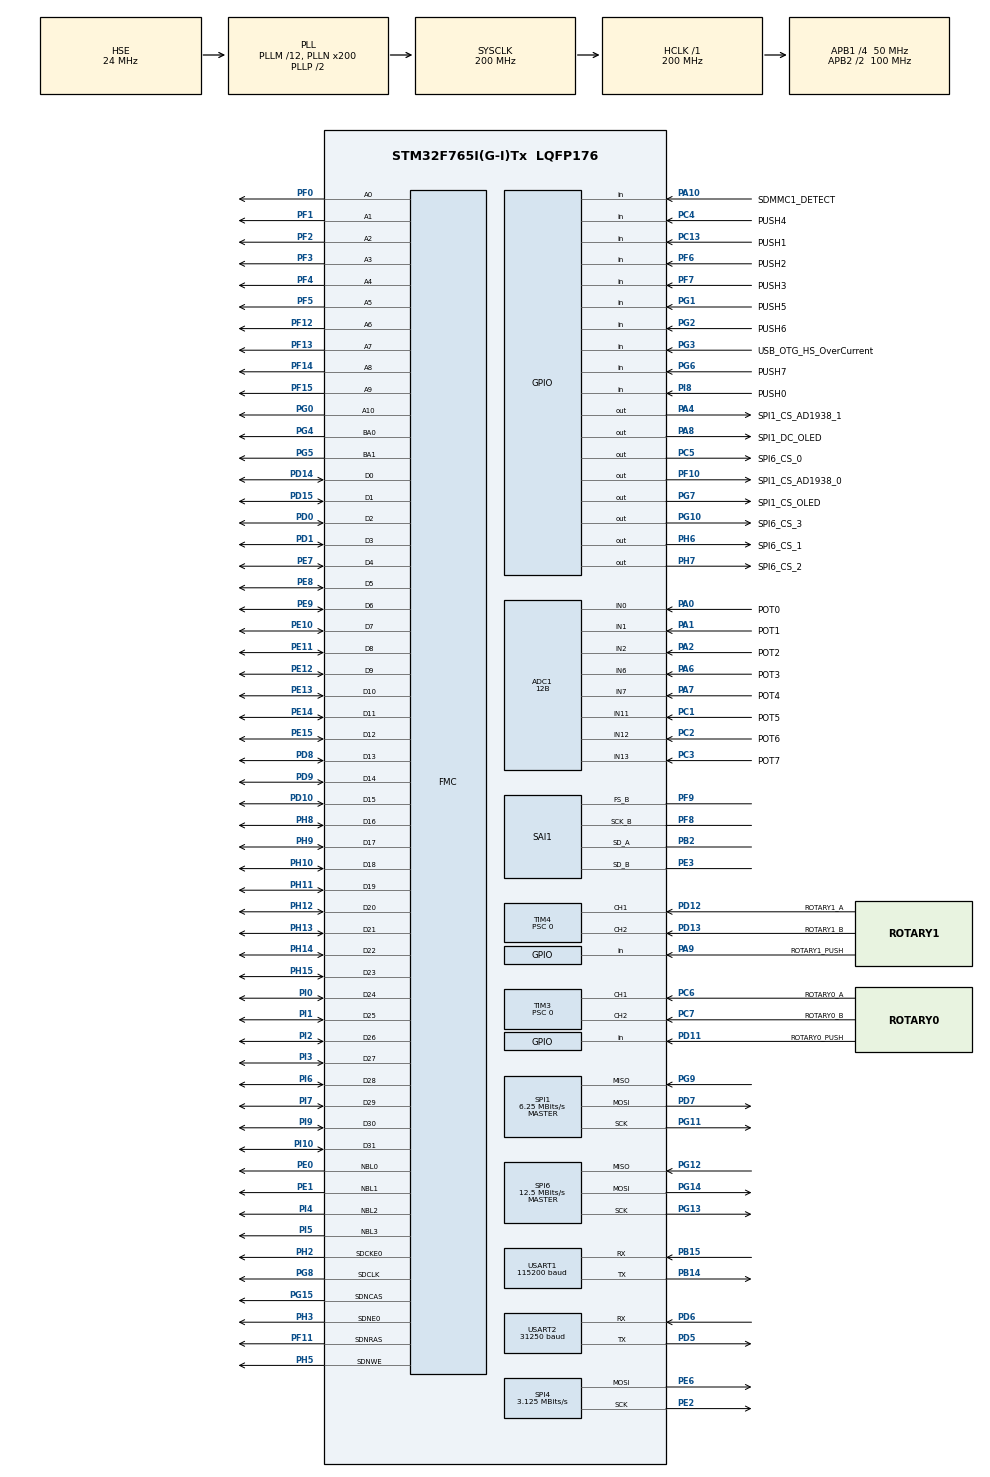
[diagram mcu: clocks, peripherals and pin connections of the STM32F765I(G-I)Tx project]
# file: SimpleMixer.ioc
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ADC1.Channel-0\#ChannelRegularConversion=ADC_CHANNEL_0
ADC1.Channel-1\#ChannelRegularConversion=ADC_CHANNEL_1
ADC1.Channel-2\#ChannelRegularConversion=ADC_CHANNEL_2
ADC1.Channel-3\#ChannelRegularConversion=ADC_CHANNEL_6
ADC1.Channel-4\#ChannelRegularConversion=ADC_CHANNEL_7
ADC1.Channel-5\#ChannelRegularConversion=ADC_CHANNEL_11
ADC1.Channel-6\#ChannelRegularConversion=ADC_CHANNEL_12
ADC1.Channel-7\#ChannelRegularConversion=ADC_CHANNEL_13
ADC1.ClockPrescaler=ADC_CLOCK_SYNC_PCLK_DIV8
ADC1.ContinuousConvMode=ENABLE
ADC1.DMAContinuousRequests=ENABLE
ADC1.DataAlign=ADC_DATAALIGN_RIGHT
ADC1.DiscontinuousConvMode=DISABLE
ADC1.EOCSelection=ADC_EOC_SEQ_CONV
ADC1.EnableAnalogWatchDog=false
ADC1.ExternalTrigConv=ADC_SOFTWARE_START
ADC1.ExternalTrigConvEdge=ADC_EXTERNALTRIGCONVEDGE_NONE
ADC1.InjNumberOfConversion=0
ADC1.NbrOfConversion=8
ADC1.NbrOfConversionFlag=1
ADC1.Rank-0\#ChannelRegularConversion=1
ADC1.Rank-1\#ChannelRegularConversion=2
ADC1.Rank-2\#ChannelRegularConversion=3
ADC1.Rank-3\#ChannelRegularConversion=4
ADC1.Rank-4\#ChannelRegularConversion=5
ADC1.Rank-5\#ChannelRegularConversion=6
ADC1.Rank-6\#ChannelRegularConversion=7
ADC1.Rank-7\#ChannelRegularConversion=8
ADC1.Resolution=ADC_RESOLUTION_12B
ADC1.SamplingTime-0\#ChannelRegularConversion=ADC_SAMPLETIME_480CYCLES
ADC1.SamplingTime-1\#ChannelRegularConversion=ADC_SAMPLETIME_480CYCLES
ADC1.SamplingTime-2\#ChannelRegularConversion=ADC_SAMPLETIME_480CYCLES
ADC1.SamplingTime-3\#ChannelRegularConversion=ADC_SAMPLETIME_480CYCLES
ADC1.SamplingTime-4\#ChannelRegularConversion=ADC_SAMPLETIME_480CYCLES
ADC1.SamplingTime-5\#ChannelRegularConversion=ADC_SAMPLETIME_480CYCLES
ADC1.SamplingTime-6\#ChannelRegularConversion=ADC_SAMPLETIME_480CYCLES
ADC1.SamplingTime-7\#ChannelRegularConversion=ADC_SAMPLETIME_480CYCLES
ADC1.ScanConvMode=ENABLE
ADC1.master=1
CORTEX_M7.FlashInterface=TCM_Enabled
Dma.ADC1.0.Direction=DMA_PERIPH_TO_MEMORY
Dma.ADC1.0.FIFOMode=DMA_FIFOMODE_DISABLE
Dma.ADC1.0.Instance=DMA2_Stream4
Dma.ADC1.0.MemDataAlignment=DMA_MDATAALIGN_HALFWORD
Dma.ADC1.0.MemInc=DMA_MINC_ENABLE
Dma.ADC1.0.Mode=DMA_CIRCULAR
Dma.ADC1.0.PeriphDataAlignment=DMA_PDATAALIGN_HALFWORD
Dma.ADC1.0.PeriphInc=DMA_PINC_DISABLE
Dma.ADC1.0.Priority=DMA_PRIORITY_LOW
Dma.Request0=ADC1
Dma.Request1=SAI1_A
Dma.Request2=SAI1_B
Dma.Request3=SPI4_TX
Dma.SAI1_A.1.Direction=DMA_PERIPH_TO_MEMORY
Dma.SAI1_A.1.FIFOMode=DMA_FIFOMODE_ENABLE
Dma.SAI1_A.1.FIFOThreshold=DMA_FIFO_THRESHOLD_HALFFULL
Dma.SAI1_A.1.Instance=DMA2_Stream1
Dma.SAI1_A.1.MemBurst=DMA_MBURST_SINGLE
Dma.SAI1_A.1.MemDataAlignment=DMA_MDATAALIGN_WORD
Dma.SAI1_A.1.MemInc=DMA_MINC_ENABLE
Dma.SAI1_A.1.Mode=DMA_CIRCULAR
Dma.SAI1_A.1.PeriphBurst=DMA_PBURST_SINGLE
Dma.SAI1_A.1.PeriphDataAlignment=DMA_PDATAALIGN_WORD
Dma.SAI1_A.1.PeriphInc=DMA_PINC_DISABLE
Dma.SAI1_A.1.Priority=DMA_PRIORITY_HIGH
Dma.SAI1_B.2.Direction=DMA_MEMORY_TO_PERIPH
Dma.SAI1_B.2.FIFOMode=DMA_FIFOMODE_ENABLE
Dma.SAI1_B.2.FIFOThreshold=DMA_FIFO_THRESHOLD_HALFFULL
Dma.SAI1_B.2.Instance=DMA2_Stream0
Dma.SAI1_B.2.MemBurst=DMA_MBURST_SINGLE
Dma.SAI1_B.2.MemDataAlignment=DMA_MDATAALIGN_WORD
Dma.SAI1_B.2.MemInc=DMA_MINC_ENABLE
Dma.SAI1_B.2.Mode=DMA_CIRCULAR
Dma.SAI1_B.2.PeriphBurst=DMA_PBURST_SINGLE
Dma.SAI1_B.2.PeriphDataAlignment=DMA_PDATAALIGN_WORD
Dma.SAI1_B.2.PeriphInc=DMA_PINC_DISABLE
Dma.SAI1_B.2.Priority=DMA_PRIORITY_HIGH
Dma.SPI4_TX.3.Direction=DMA_MEMORY_TO_PERIPH
Dma.SPI4_TX.3.FIFOMode=DMA_FIFOMODE_ENABLE
Dma.SPI4_TX.3.FIFOThreshold=DMA_FIFO_THRESHOLD_FULL
Dma.SPI4_TX.3.Instance=DMA2_Stream2
Dma.SPI4_TX.3.MemBurst=DMA_MBURST_INC8
Dma.SPI4_TX.3.MemDataAlignment=DMA_MDATAALIGN_BYTE
Dma.SPI4_TX.3.MemInc=DMA_MINC_ENABLE
Dma.SPI4_TX.3.Mode=DMA_NORMAL
Dma.SPI4_TX.3.PeriphBurst=DMA_PBURST_SINGLE
Dma.SPI4_TX.3.PeriphDataAlignment=DMA_PDATAALIGN_BYTE
Dma.SPI4_TX.3.PeriphInc=DMA_PINC_DISABLE
Dma.SPI4_TX.3.Priority=DMA_PRIORITY_VERY_HIGH
FMC.CASLatency1=FMC_SDRAM_CAS_LATENCY_2
FMC.ExitSelfRefreshDelay1=7
FMC.LoadToActiveDelay1=2
FMC.RCDDelay1=2
FMC.RPDelay1=2
FMC.RPDelay2=2
FMC.ReadBurst1=FMC_SDRAM_RBURST_ENABLE
FMC.ReadBurst2=FMC_SDRAM_RBURST_ENABLE
FMC.ReadPipeDelay1=FMC_SDRAM_RPIPE_DELAY_0
FMC.RowCycleDelay1=7
FMC.RowCycleDelay2=7
FMC.SDClockPeriod1=FMC_SDRAM_CLOCK_PERIOD_2
FMC.SDClockPeriod2=FMC_SDRAM_CLOCK_PERIOD_2
FMC.SelfRefreshTime1=5
FMC.WriteRecoveryTime1=3
FREERTOS.INCLUDE_uxTaskGetStackHighWaterMark=1
FREERTOS.INCLUDE_vTaskDelayUntil=1
FREERTOS.Tasks01=audio,3,32768,audioTask,Default,NULL,Dynamic,NULL,NULL;GUI,-2,32768,guiTask,Default,NULL,Dynamic,NULL,NULL
FREERTOS.configGENERATE_RUN_TIME_STATS=0
FREERTOS.configTOTAL_HEAP_SIZE=393216
Mcu.Family=STM32F7
Mcu.Name=STM32F765I(G-I)Tx
Mcu.Package=LQFP176
NVIC.DMA2_Stream0_IRQn=true\:5\:0\:false\:false\:true\:true\:false
NVIC.DMA2_Stream1_IRQn=true\:5\:0\:false\:false\:true\:true\:false
NVIC.DMA2_Stream2_IRQn=true\:5\:0\:false\:false\:true\:true\:false
NVIC.DMA2_Stream4_IRQn=true\:5\:0\:false\:false\:true\:true\:false
NVIC.PriorityGroup=NVIC_PRIORITYGROUP_4
NVIC.TIM1_UP_TIM10_IRQn=true\:0\:0\:false\:false\:true\:false\:true
NVIC.TimeBase=TIM1_UP_TIM10_IRQn
NVIC.TimeBaseIP=TIM1
PA0/WKUP.GPIO_Label=POT0
PA0/WKUP.Signal=ADCx_IN0
PA1.GPIO_Label=POT1
PA1.Signal=ADCx_IN1
PA10.GPIO_Label=SDMMC1_DETECT
PA10.GPIO_PuPd=GPIO_PULLUP
PA10.Signal=GPIO_Input
PA13.Mode=Trace_Asynchronous_SW
PA13.Signal=SYS_JTMS-SWDIO
PA14.Mode=Trace_Asynchronous_SW
PA14.Signal=SYS_JTCK-SWCLK
PA2.GPIO_Label=POT2
PA2.Signal=ADCx_IN2
PA3.Signal=USB_OTG_HS_ULPI_D0
PA4.GPIO_Label=SPI1_CS_AD1938_1
PA4.Signal=GPIO_Output
PA5.Signal=USB_OTG_HS_ULPI_CK
PA6.GPIO_Label=POT3
PA6.Signal=ADCx_IN6
PA7.GPIO_Label=POT4
PA7.Signal=ADCx_IN7
PA8.GPIO_Label=SPI1_DC_OLED
PA8.PinState=GPIO_PIN_RESET
PA8.Signal=GPIO_Output
PA9.GPIO_Label=ROTARY1_PUSH
PA9.GPIO_Mode=GPIO_MODE_INPUT
PA9.GPIO_PuPd=GPIO_PULLUP
PA9.Signal=GPIO_Input
PB0.Signal=USB_OTG_HS_ULPI_D1
PB1.Signal=USB_OTG_HS_ULPI_D2
PB10.Signal=USB_OTG_HS_ULPI_D3
PB11.Signal=USB_OTG_HS_ULPI_D4
PB12.Signal=USB_OTG_HS_ULPI_D5
PB13.Signal=USB_OTG_HS_ULPI_D6
PB14.Mode=Asynchronous
PB14.Signal=USART1_TX
PB15.Mode=Asynchronous
PB15.Signal=USART1_RX
PB2.Mode=SAI_A_SyncSlave
PB2.Signal=SAI1_SD_A
PB3.Mode=Trace_Asynchronous_SW
PB3.Signal=SYS_JTDO-SWO
PB5.Signal=USB_OTG_HS_ULPI_D7
PC0.Signal=USB_OTG_HS_ULPI_STP
PC1.GPIO_Label=POT5
PC1.Signal=ADCx_IN11
PC10.Signal=SDMMC1_D2
PC11.Signal=SDMMC1_D3
PC12.Signal=SDMMC1_CK
PC13.GPIO_Label=PUSH1
PC13.GPIO_Mode=GPIO_MODE_INPUT
PC13.GPIO_PuPd=GPIO_PULLUP
PC13.Signal=GPIO_Input
PC14/OSC32_IN.Signal=RCC_OSC32_IN
PC15/OSC32_OUT.Signal=RCC_OSC32_OUT
PC2.GPIO_Label=POT6
PC2.Signal=ADCx_IN12
PC3.GPIO_Label=POT7
PC3.Signal=ADCx_IN13
PC4.GPIO_Label=PUSH4
PC4.GPIO_Mode=GPIO_MODE_INPUT
PC4.GPIO_PuPd=GPIO_PULLUP
PC4.Signal=GPIO_Input
PC5.GPIO_Label=SPI6_CS_0
PC5.PinState=GPIO_PIN_RESET
PC5.Signal=GPIO_Output
PC6.GPIO_Label=ROTARY0_A
PC6.Signal=S_TIM3_CH1
PC7.GPIO_Label=ROTARY0_B
PC7.Signal=S_TIM3_CH2
PC8.Signal=SDMMC1_D0
PC9.Signal=SDMMC1_D1
PD0.Signal=FMC_D2_DA2
PD1.Signal=FMC_D3_DA3
PD10.Signal=FMC_D15_DA15
PD11.GPIO_Label=ROTARY0_PUSH
PD11.GPIO_Mode=GPIO_MODE_INPUT
PD11.GPIO_PuPd=GPIO_PULLUP
PD11.Signal=GPIO_Input
PD12.GPIO_Label=ROTARY1_A
PD12.Signal=S_TIM4_CH1
PD13.GPIO_Label=ROTARY1_B
PD13.Signal=S_TIM4_CH2
PD14.Signal=FMC_D0_DA0
PD15.Signal=FMC_D1_DA1
PD2.Signal=SDMMC1_CMD
PD5.Mode=Asynchronous
PD5.Signal=USART2_TX
PD6.Mode=Asynchronous
PD6.Signal=USART2_RX
PD7.Mode=Full_Duplex_Master
PD7.Signal=SPI1_MOSI
PD8.Signal=FMC_D13_DA13
PD9.Signal=FMC_D14_DA14
PE0.Signal=FMC_NBL0
PE1.Signal=FMC_NBL1
PE10.Signal=FMC_D7_DA7
PE11.Signal=FMC_D8_DA8
PE12.Signal=FMC_D9_DA9
PE13.Signal=FMC_D10_DA10
PE14.Signal=FMC_D11_DA11
PE15.Signal=FMC_D12_DA12
PE2.Mode=TX_Only_Simplex_Unidirect_Master
PE2.Signal=SPI4_SCK
PE3.Mode=SAI_B_AsyncSlave
PE3.Signal=SAI1_SD_B
PE4.Signal=SAI1_FS_A
PE5.Signal=SAI1_SCK_A
PE6.Mode=TX_Only_Simplex_Unidirect_Master
PE6.Signal=SPI4_MOSI
PE7.Signal=FMC_D4_DA4
PE8.Signal=FMC_D5_DA5
PE9.Signal=FMC_D6_DA6
PF0.Signal=FMC_A0
PF1.Signal=FMC_A1
PF10.GPIO_Label=SPI1_CS_AD1938_0
PF10.PinState=GPIO_PIN_RESET
PF10.Signal=GPIO_Output
PF11.Signal=FMC_SDNRAS
PF12.Signal=FMC_A6
PF13.Signal=FMC_A7
PF14.Signal=FMC_A8
PF15.Signal=FMC_A9
PF2.Signal=FMC_A2
PF3.Signal=FMC_A3
PF4.Signal=FMC_A4
PF5.Signal=FMC_A5
PF6.GPIO_Label=PUSH2
PF6.GPIO_Mode=GPIO_MODE_INPUT
PF6.GPIO_PuPd=GPIO_PULLUP
PF6.Signal=GPIO_Input
PF7.GPIO_Label=PUSH3
PF7.GPIO_Mode=GPIO_MODE_INPUT
PF7.GPIO_PuPd=GPIO_PULLUP
PF7.Signal=GPIO_Input
PF8.Mode=SAI_B_AsyncSlave
PF8.Signal=SAI1_SCK_B
PF9.Mode=SAI_B_AsyncSlave
PF9.Signal=SAI1_FS_B
PG0.Signal=FMC_A10
PG1.GPIO_Label=PUSH5
PG1.GPIO_Mode=GPIO_MODE_INPUT
PG1.GPIO_PuPd=GPIO_PULLUP
PG1.Signal=GPIO_Input
PG10.GPIO_Label=SPI6_CS_3
PG10.PinState=GPIO_PIN_RESET
PG10.Signal=GPIO_Output
PG11.Mode=Full_Duplex_Master
PG11.Signal=SPI1_SCK
PG12.Mode=Full_Duplex_Master
PG12.Signal=SPI6_MISO
PG13.Mode=Full_Duplex_Master
PG13.Signal=SPI6_SCK
PG14.Mode=Full_Duplex_Master
PG14.Signal=SPI6_MOSI
PG15.Signal=FMC_SDNCAS
PG2.GPIO_Label=PUSH6
PG2.GPIO_Mode=GPIO_MODE_INPUT
PG2.GPIO_PuPd=GPIO_PULLUP
PG2.Signal=GPIO_Input
PG3.GPIO_Label=USB_OTG_HS_OverCurrent
PG3.Signal=GPIO_Input
PG4.Signal=FMC_A14_BA0
PG5.Signal=FMC_A15_BA1
PG6.GPIO_Label=PUSH7
PG6.GPIO_Mode=GPIO_MODE_INPUT
PG6.GPIO_PuPd=GPIO_PULLUP
PG6.Signal=GPIO_Input
PG7.GPIO_Label=SPI1_CS_OLED
PG7.PinState=GPIO_PIN_RESET
PG7.Signal=GPIO_Output
PG8.Signal=FMC_SDCLK
PG9.Mode=Full_Duplex_Master
PG9.Signal=SPI1_MISO
PH0/OSC_IN.Mode=HSE-External-Clock-Source
PH0/OSC_IN.Signal=RCC_OSC_IN
PH1/OSC_OUT.Mode=HSE-External-Clock-Source
PH1/OSC_OUT.Signal=RCC_OSC_OUT
PH10.Signal=FMC_D18
PH11.Signal=FMC_D19
PH12.Signal=FMC_D20
PH13.Signal=FMC_D21
PH14.Signal=FMC_D22
PH15.Signal=FMC_D23
PH2.Mode=SdramChipSelect1_1
PH2.Signal=FMC_SDCKE0
PH3.Mode=SdramChipSelect1_1
PH3.Signal=FMC_SDNE0
PH4.Signal=USB_OTG_HS_ULPI_NXT
PH5.Signal=FMC_SDNWE
PH6.GPIO_Label=SPI6_CS_1
PH6.PinState=GPIO_PIN_RESET
PH6.Signal=GPIO_Output
PH7.GPIO_Label=SPI6_CS_2
PH7.PinState=GPIO_PIN_RESET
PH7.Signal=GPIO_Output
PH8.Signal=FMC_D16
PH9.Signal=FMC_D17
PI0.Signal=FMC_D24
PI1.Signal=FMC_D25
PI10.Signal=FMC_D31
PI11.Signal=USB_OTG_HS_ULPI_DIR
PI2.Signal=FMC_D26
PI3.Signal=FMC_D27
PI4.Signal=FMC_NBL2
PI5.Signal=FMC_NBL3
PI6.Signal=FMC_D28
PI7.Signal=FMC_D29
PI8.GPIO_Label=PUSH0
PI8.GPIO_Mode=GPIO_MODE_INPUT
PI8.GPIO_PuPd=GPIO_PULLUP
PI8.Signal=GPIO_Input
PI9.Signal=FMC_D30
ProjectManager.HeapSize=0x200
ProjectManager.StackSize=0x400
ProjectManager.TargetToolchain=SW4STM32
RCC.AHBFreq_Value=200000000
RCC.APB1CLKDivider=RCC_HCLK_DIV4
RCC.APB1Freq_Value=50000000
RCC.APB1TimFreq_Value=100000000
RCC.APB2CLKDivider=RCC_HCLK_DIV2
RCC.APB2Freq_Value=100000000
RCC.APB2TimFreq_Value=200000000
RCC.CortexFreq_Value=200000000
RCC.HCLKFreq_Value=200000000
RCC.HSE_VALUE=24000000
RCC.HSI_VALUE=16000000
RCC.LSE_VALUE=32768
RCC.PLL48CLockSelection=RCC_CLK48SOURCE_PLLSAIP
RCC.PLLM=12
RCC.PLLN=200
RCC.PLLQ=10
RCC.PLLSAIP=RCC_PLLSAIP_DIV8
RCC.PLLSAIQ=6
RCC.PLLSourceVirtual=RCC_PLLSOURCE_HSE
RCC.RTCClockSelection=RCC_RTCCLKSOURCE_LSE
RCC.SDMMCClockSelection=RCC_SDMMC1CLKSOURCE_CLK48
RCC.SYSCLKFreq_VALUE=200000000
RCC.SYSCLKSource=RCC_SYSCLKSOURCE_PLLCLK
RCC.USART1CLockSelection=RCC_USART1CLKSOURCE_SYSCLK
RCC.USBFreq_Value=48000000
RCC.VCOOutputFreq_Value=400000000
SAI1.AudioMode-SAI_B_AsyncSlave=SAI_MODESLAVE_TX
SAI1.BasicDataSize-SAI_A_SyncSlave=SAI_PROTOCOL_DATASIZE_32BIT
SAI1.BasicDataSize-SAI_B_AsyncSlave=SAI_PROTOCOL_DATASIZE_32BIT
SAI1.BasicSlotNumber-SAI_A_SyncSlave=8
SAI1.BasicSlotNumber-SAI_B_AsyncSlave=8
SAI1.FIFOThreshold-SAI_B_AsyncSlave=SAI_FIFOTHRESHOLD_FULL
SAI1.InitProtocol-SAI_A_SyncSlave=Enable
SAI1.InitProtocol-SAI_B_AsyncSlave=Enable
SAI1.Instance-SAI_A_SyncSlave=SAI$Index_Block_A
SAI1.Instance-SAI_B_AsyncSlave=SAI$Index_Block_B
SAI1.OutputDrive-SAI_B_AsyncSlave=SAI_OUTPUTDRIVE_ENABLE
SAI1.Synchro-SAI_A_SyncSlave=SAI_SYNCHRONOUS
SAI1.Synchro-SAI_B_AsyncSlave=SAI_ASYNCHRONOUS
SAI1.SynchroExt-SAI_B_AsyncSlave=SAI_SYNCEXT_DISABLE
SAI1.VirtualMode-SAI_A_SyncSlave=VM_SLAVE
SAI1.VirtualMode-SAI_B_AsyncSlave=VM_SLAVE
SAI1.VirtualProtocol-SAI_A_BASIC=VM_BASIC_PROTOCOL
SAI1.VirtualProtocol-SAI_B_BASIC=VM_BASIC_PROTOCOL
SH.ADCx_IN0.0=ADC1_IN0,IN0
SH.ADCx_IN1.0=ADC1_IN1,IN1
SH.ADCx_IN11.0=ADC1_IN11,IN11
SH.ADCx_IN12.0=ADC1_IN12,IN12
SH.ADCx_IN13.0=ADC1_IN13,IN13
SH.ADCx_IN2.0=ADC1_IN2,IN2
SH.ADCx_IN6.0=ADC1_IN6,IN6
SH.ADCx_IN7.0=ADC1_IN7,IN7
SH.FMC_A0.0=FMC_A0,11b-sda1
SH.FMC_A1.0=FMC_A1,11b-sda1
SH.FMC_A10.0=FMC_A10,11b-sda1
SH.FMC_A14_BA0.0=FMC_BA0,FourSdramBanks1
SH.FMC_A15_BA1.0=FMC_BA1,FourSdramBanks1
SH.FMC_A2.0=FMC_A2,11b-sda1
SH.FMC_A3.0=FMC_A3,11b-sda1
SH.FMC_A4.0=FMC_A4,11b-sda1
SH.FMC_A5.0=FMC_A5,11b-sda1
SH.FMC_A6.0=FMC_A6,11b-sda1
SH.FMC_A7.0=FMC_A7,11b-sda1
SH.FMC_A8.0=FMC_A8,11b-sda1
SH.FMC_A9.0=FMC_A9,11b-sda1
SH.FMC_D0_DA0.0=FMC_D0,sd-32b-d1
SH.FMC_D10_DA10.0=FMC_D10,sd-32b-d1
SH.FMC_D11_DA11.0=FMC_D11,sd-32b-d1
SH.FMC_D12_DA12.0=FMC_D12,sd-32b-d1
SH.FMC_D13_DA13.0=FMC_D13,sd-32b-d1
SH.FMC_D14_DA14.0=FMC_D14,sd-32b-d1
SH.FMC_D15_DA15.0=FMC_D15,sd-32b-d1
SH.FMC_D16.0=FMC_D16,sd-32b-d1
SH.FMC_D17.0=FMC_D17,sd-32b-d1
SH.FMC_D18.0=FMC_D18,sd-32b-d1
SH.FMC_D19.0=FMC_D19,sd-32b-d1
SH.FMC_D1_DA1.0=FMC_D1,sd-32b-d1
SH.FMC_D20.0=FMC_D20,sd-32b-d1
SH.FMC_D21.0=FMC_D21,sd-32b-d1
SH.FMC_D22.0=FMC_D22,sd-32b-d1
SH.FMC_D23.0=FMC_D23,sd-32b-d1
SH.FMC_D24.0=FMC_D24,sd-32b-d1
SH.FMC_D25.0=FMC_D25,sd-32b-d1
SH.FMC_D26.0=FMC_D26,sd-32b-d1
SH.FMC_D27.0=FMC_D27,sd-32b-d1
SH.FMC_D28.0=FMC_D28,sd-32b-d1
SH.FMC_D29.0=FMC_D29,sd-32b-d1
SH.FMC_D2_DA2.0=FMC_D2,sd-32b-d1
SH.FMC_D30.0=FMC_D30,sd-32b-d1
SH.FMC_D31.0=FMC_D31,sd-32b-d1
SH.FMC_D3_DA3.0=FMC_D3,sd-32b-d1
SH.FMC_D4_DA4.0=FMC_D4,sd-32b-d1
SH.FMC_D5_DA5.0=FMC_D5,sd-32b-d1
SH.FMC_D6_DA6.0=FMC_D6,sd-32b-d1
SH.FMC_D7_DA7.0=FMC_D7,sd-32b-d1
SH.FMC_D8_DA8.0=FMC_D8,sd-32b-d1
SH.FMC_D9_DA9.0=FMC_D9,sd-32b-d1
SH.FMC_NBL0.0=FMC_NBL0,Sd4ByteEnable1
SH.FMC_NBL1.0=FMC_NBL1,Sd4ByteEnable1
SH.FMC_NBL2.0=FMC_NBL2,Sd4ByteEnable1
SH.FMC_NBL3.0=FMC_NBL3,Sd4ByteEnable1
SH.FMC_SDCLK.0=FMC_SDCLK,11b-sda1
SH.FMC_SDNCAS.0=FMC_SDNCAS,11b-sda1
SH.FMC_SDNRAS.0=FMC_SDNRAS,11b-sda1
SH.FMC_SDNWE.0=FMC_SDNWE,11b-sda1
SH.S_TIM3_CH1.0=TIM3_CH1,Encoder_Interface
SH.S_TIM3_CH2.0=TIM3_CH2,Encoder_Interface
SH.S_TIM4_CH1.0=TIM4_CH1,Encoder_Interface
SH.S_TIM4_CH2.0=TIM4_CH2,Encoder_Interface
SPI1.BaudRatePrescaler=SPI_BAUDRATEPRESCALER_16
SPI1.CLKPhase=SPI_PHASE_2EDGE
SPI1.CLKPolarity=SPI_POLARITY_HIGH
SPI1.CalculateBaudRate=6.25 MBits/s
SPI1.DataSize=SPI_DATASIZE_8BIT
SPI1.Direction=SPI_DIRECTION_2LINES
SPI1.Mode=SPI_MODE_MASTER
SPI1.VirtualType=VM_MASTER
SPI4.BaudRatePrescaler=SPI_BAUDRATEPRESCALER_32
SPI4.CalculateBaudRate=3.125 MBits/s
SPI4.DataSize=SPI_DATASIZE_8BIT
SPI4.Direction=SPI_DIRECTION_2LINES
SPI4.Mode=SPI_MODE_MASTER
SPI4.NSSPMode=SPI_NSS_PULSE_DISABLE
SPI4.VirtualType=VM_MASTER
SPI6.BaudRatePrescaler=SPI_BAUDRATEPRESCALER_8
SPI6.CLKPolarity=SPI_POLARITY_HIGH
SPI6.CalculateBaudRate=12.5 MBits/s
SPI6.DataSize=SPI_DATASIZE_16BIT
SPI6.Direction=SPI_DIRECTION_2LINES
SPI6.Mode=SPI_MODE_MASTER
SPI6.NSSPMode=SPI_NSS_PULSE_DISABLE
SPI6.VirtualType=VM_MASTER
TIM2.Period=4294967295
TIM2.Prescaler=0
TIM3.ClockDivision=TIM_CLOCKDIVISION_DIV1
TIM3.CounterMode=TIM_COUNTERMODE_UP
TIM3.EncoderMode=TIM_ENCODERMODE_TI12
TIM3.IC1Filter=15
TIM3.IC1Polarity=TIM_ICPOLARITY_FALLING
TIM3.IC1Prescaler=TIM_ICPSC_DIV1
TIM3.IC2Filter=15
TIM3.IC2Polarity=TIM_ICPOLARITY_FALLING
TIM3.IC2Prescaler=TIM_ICPSC_DIV1
TIM3.Period=65535
TIM3.Prescaler=0
TIM4.ClockDivision=TIM_CLOCKDIVISION_DIV1
TIM4.EncoderMode=TIM_ENCODERMODE_TI12
TIM4.IC1Filter=15
TIM4.IC1Polarity=TIM_ICPOLARITY_FALLING
TIM4.IC2Filter=15
TIM4.IC2Polarity=TIM_ICPOLARITY_FALLING
TIM4.Period=65535
TIM4.Prescaler=0
TIM6.AutoReloadPreload=TIM_AUTORELOAD_PRELOAD_ENABLE
TIM6.Period=65535
USART1.BaudRate=115200
USART1.Parity=PARITY_NONE
USART1.StopBits=STOPBITS_1
USART1.VirtualMode-Asynchronous=VM_ASYNC
USART1.WordLength=WORDLENGTH_8B
USART2.BaudRate=31250
USART2.VirtualMode-Asynchronous=VM_ASYNC
USART2.WordLength=WORDLENGTH_8B
VP_FREERTOS_VS_ENABLE.Mode=Enabled
VP_RNG_VS_RNG.Mode=RNG_Activate
VP_SAI1_VP_$IpInstance_SAIA_SAI_BASIC.Mode=SAI_A_BASIC
VP_SAI1_VP_$IpInstance_SAIB_SAI_BASIC.Mode=SAI_B_BASIC
VP_SYS_VS_tim1.Mode=TIM1
VP_TIM2_VS_ClockSourceINT.Mode=Internal
VP_TIM6_VS_ClockSourceINT.Mode=Enable_Timer
board=SimpleMixer

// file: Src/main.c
/**
  ******************************************************************************
  * @file           : main.c
  * @brief          : Main program body
  ******************************************************************************
  * This notice applies to any and all portions of this file
  * that are not between comment pairs USER CODE BEGIN and
  * USER CODE END. Other portions of this file, whether
  * inserted by the user or by software development tools
  * are owned by their respective copyright owners.
  *
  * Copyright (c) 2018 STMicroelectronics International N.V.
  * All rights reserved.
  *
  * Redistribution and use in source and binary forms, with or without
  * modification, are permitted, provided that the following conditions are met:
  *
  * 1. Redistribution of source code must retain the above copyright notice,
  *    this list of conditions and the following disclaimer.
  * 2. Redistributions in binary form must reproduce the above copyright notice,
  *    this list of conditions and the following disclaimer in the documentation
  *    and/or other materials provided with the distribution.
  * 3. Neither the name of STMicroelectronics nor the names of other
  *    contributors to this software may be used to endorse or promote products
  *    derived from this software without specific written permission.
  * 4. This software, including modifications and/or derivative works of this
  *    software, must execute solely and exclusively on microcontroller or
  *    microprocessor devices manufactured by or for STMicroelectronics.
  * 5. Redistribution and use of this software other than as permitted under
  *    this license is void and will automatically terminate your rights under
  *    this license.
  *
  * THIS SOFTWARE IS PROVIDED BY STMICROELECTRONICS AND CONTRIBUTORS "AS IS"
  * AND ANY EXPRESS, IMPLIED OR STATUTORY WARRANTIES, INCLUDING, BUT NOT
  * LIMITED TO, THE IMPLIED WARRANTIES OF MERCHANTABILITY, FITNESS FOR A
  * PARTICULAR PURPOSE AND NON-INFRINGEMENT OF THIRD PARTY INTELLECTUAL PROPERTY
  * RIGHTS ARE DISCLAIMED TO THE FULLEST EXTENT PERMITTED BY LAW. IN NO EVENT
  * SHALL STMICROELECTRONICS OR CONTRIBUTORS BE LIABLE FOR ANY DIRECT, INDIRECT,
  * INCIDENTAL, SPECIAL, EXEMPLARY, OR CONSEQUENTIAL DAMAGES (INCLUDING, BUT NOT
  * LIMITED TO, PROCUREMENT OF SUBSTITUTE GOODS OR SERVICES; LOSS OF USE, DATA,
  * OR PROFITS; OR BUSINESS INTERRUPTION) HOWEVER CAUSED AND ON ANY THEORY OF
  * LIABILITY, WHETHER IN CONTRACT, STRICT LIABILITY, OR TORT (INCLUDING
  * NEGLIGENCE OR OTHERWISE) ARISING IN ANY WAY OUT OF THE USE OF THIS SOFTWARE,
  * EVEN IF ADVISED OF THE POSSIBILITY OF SUCH DAMAGE.
  *
  ******************************************************************************
  */
#include "main.h"
#include "stm32f7xx_hal.h"
#include "cmsis_os.h"
#include "adc.h"
#include "dma.h"
#include "rng.h"
#include "sai.h"
#include "spi.h"
#include "tim.h"
#include "usart.h"
#include "gpio.h"
#include "fmc.h"

/* USER CODE BEGIN PV */
/* Private variables ---------------------------------------------------------*/

/* USER CODE END PV */

void SystemClock_Config(void);
void MX_FREERTOS_Init(void);

/* USER CODE BEGIN PFP */
/* Private function prototypes -----------------------------------------------*/

/* USER CODE END PFP */

int main(void)
{

  /* MCU Configuration----------------------------------------------------------*/

  /* Reset of all peripherals, Initializes the Flash interface and the Systick. */
  HAL_Init();

  /* Configure the system clock */
  SystemClock_Config();

  /* Initialize all configured peripherals */
  MX_GPIO_Init();
  MX_DMA_Init();
  MX_ADC1_Init();
  MX_FMC_Init();
  MX_RNG_Init();
  MX_SAI1_Init();
  MX_SPI1_Init();
  MX_SPI4_Init();
  MX_SPI6_Init();
  MX_TIM3_Init();
  MX_TIM4_Init();
  MX_USART1_UART_Init();
  MX_USART2_UART_Init();
  MX_TIM2_Init();
  MX_TIM6_Init();

  /* Call init function for freertos objects (in freertos.c) */
  MX_FREERTOS_Init();

  /* Start scheduler */
  osKernelStart();

  /* We should never get here as control is now taken by the scheduler */

  /* Infinite loop */
  while (1)
  {

  }

}

void SystemClock_Config(void)
{

  RCC_OscInitTypeDef RCC_OscInitStruct;
  RCC_ClkInitTypeDef RCC_ClkInitStruct;
  RCC_PeriphCLKInitTypeDef PeriphClkInitStruct;

    /**Configure the main internal regulator output voltage
    */
  __HAL_RCC_PWR_CLK_ENABLE();

  __HAL_PWR_VOLTAGESCALING_CONFIG(PWR_REGULATOR_VOLTAGE_SCALE1);

    /**Initializes the CPU, AHB and APB busses clocks
    */
  RCC_OscInitStruct.OscillatorType = RCC_OSCILLATORTYPE_HSE;
  RCC_OscInitStruct.HSEState = RCC_HSE_BYPASS;
  RCC_OscInitStruct.PLL.PLLState = RCC_PLL_ON;
  RCC_OscInitStruct.PLL.PLLSource = RCC_PLLSOURCE_HSE;
  RCC_OscInitStruct.PLL.PLLM = 12;
  RCC_OscInitStruct.PLL.PLLN = 200;
  RCC_OscInitStruct.PLL.PLLP = RCC_PLLP_DIV2;
  RCC_OscInitStruct.PLL.PLLQ = 10;
  if (HAL_RCC_OscConfig(&RCC_OscInitStruct) != HAL_OK)
  {
    _Error_Handler(__FILE__, __LINE__);
  }

    /**Activate the Over-Drive mode
    */
  if (HAL_PWREx_EnableOverDrive() != HAL_OK)
  {
    _Error_Handler(__FILE__, __LINE__);
  }

    /**Initializes the CPU, AHB and APB busses clocks
    */
  RCC_ClkInitStruct.ClockType = RCC_CLOCKTYPE_HCLK|RCC_CLOCKTYPE_SYSCLK
                              |RCC_CLOCKTYPE_PCLK1|RCC_CLOCKTYPE_PCLK2;
  RCC_ClkInitStruct.SYSCLKSource = RCC_SYSCLKSOURCE_PLLCLK;
  RCC_ClkInitStruct.AHBCLKDivider = RCC_SYSCLK_DIV1;
  RCC_ClkInitStruct.APB1CLKDivider = RCC_HCLK_DIV4;
  RCC_ClkInitStruct.APB2CLKDivider = RCC_HCLK_DIV2;

  if (HAL_RCC_ClockConfig(&RCC_ClkInitStruct, FLASH_LATENCY_6) != HAL_OK)
  {
    _Error_Handler(__FILE__, __LINE__);
  }

  PeriphClkInitStruct.PeriphClockSelection = RCC_PERIPHCLK_USART1|RCC_PERIPHCLK_USART2
                              |RCC_PERIPHCLK_SAI1|RCC_PERIPHCLK_CLK48;
  PeriphClkInitStruct.PLLSAI.PLLSAIN = 192;
  PeriphClkInitStruct.PLLSAI.PLLSAIR = 2;
  PeriphClkInitStruct.PLLSAI.PLLSAIQ = 6;
  PeriphClkInitStruct.PLLSAI.PLLSAIP = RCC_PLLSAIP_DIV8;
  PeriphClkInitStruct.PLLSAIDivQ = 1;
  PeriphClkInitStruct.PLLSAIDivR = RCC_PLLSAIDIVR_2;
  PeriphClkInitStruct.Sai1ClockSelection = RCC_SAI1CLKSOURCE_PLLSAI;
  PeriphClkInitStruct.Usart1ClockSelection = RCC_USART1CLKSOURCE_SYSCLK;
  PeriphClkInitStruct.Usart2ClockSelection = RCC_USART2CLKSOURCE_PCLK1;
  PeriphClkInitStruct.Clk48ClockSelection = RCC_CLK48SOURCE_PLLSAIP;
  if (HAL_RCCEx_PeriphCLKConfig(&PeriphClkInitStruct) != HAL_OK)
  {
    _Error_Handler(__FILE__, __LINE__);
  }

    /**Configure the Systick interrupt time
    */
  HAL_SYSTICK_Config(HAL_RCC_GetHCLKFreq()/1000);

    /**Configure the Systick
    */
  HAL_SYSTICK_CLKSourceConfig(SYSTICK_CLKSOURCE_HCLK);

  /* SysTick_IRQn interrupt configuration */
  HAL_NVIC_SetPriority(SysTick_IRQn, 15, 0);
}

void HAL_TIM_PeriodElapsedCallback(TIM_HandleTypeDef *htim)
{
  if (htim->Instance == TIM1) {
    HAL_IncTick();
  }
}

void _Error_Handler(char *file, int line)
{
  while(1)
  {
  }
}

/************************ (C) COPYRIGHT STMicroelectronics *****END OF FILE****/

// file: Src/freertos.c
/**
  ******************************************************************************
  * File Name          : freertos.c
  * Description        : Code for freertos applications
  ******************************************************************************
  * This notice applies to any and all portions of this file
  * that are not between comment pairs USER CODE BEGIN and
  * USER CODE END. Other portions of this file, whether
  * inserted by the user or by software development tools
  * are owned by their respective copyright owners.
  *
  * Copyright (c) 2018 STMicroelectronics International N.V.
  * All rights reserved.
  *
  * Redistribution and use in source and binary forms, with or without
  * modification, are permitted, provided that the following conditions are met:
  *
  * 1. Redistribution of source code must retain the above copyright notice,
  *    this list of conditions and the following disclaimer.
  * 2. Redistributions in binary form must reproduce the above copyright notice,
  *    this list of conditions and the following disclaimer in the documentation
  *    and/or other materials provided with the distribution.
  * 3. Neither the name of STMicroelectronics nor the names of other
  *    contributors to this software may be used to endorse or promote products
  *    derived from this software without specific written permission.
  * 4. This software, including modifications and/or derivative works of this
  *    software, must execute solely and exclusively on microcontroller or
  *    microprocessor devices manufactured by or for STMicroelectronics.
  * 5. Redistribution and use of this software other than as permitted under
  *    this license is void and will automatically terminate your rights under
  *    this license.
  *
  * THIS SOFTWARE IS PROVIDED BY STMICROELECTRONICS AND CONTRIBUTORS "AS IS"
  * AND ANY EXPRESS, IMPLIED OR STATUTORY WARRANTIES, INCLUDING, BUT NOT
  * LIMITED TO, THE IMPLIED WARRANTIES OF MERCHANTABILITY, FITNESS FOR A
  * PARTICULAR PURPOSE AND NON-INFRINGEMENT OF THIRD PARTY INTELLECTUAL PROPERTY
  * RIGHTS ARE DISCLAIMED TO THE FULLEST EXTENT PERMITTED BY LAW. IN NO EVENT
  * SHALL STMICROELECTRONICS OR CONTRIBUTORS BE LIABLE FOR ANY DIRECT, INDIRECT,
  * INCIDENTAL, SPECIAL, EXEMPLARY, OR CONSEQUENTIAL DAMAGES (INCLUDING, BUT NOT
  * LIMITED TO, PROCUREMENT OF SUBSTITUTE GOODS OR SERVICES; LOSS OF USE, DATA,
  * OR PROFITS; OR BUSINESS INTERRUPTION) HOWEVER CAUSED AND ON ANY THEORY OF
  * LIABILITY, WHETHER IN CONTRACT, STRICT LIABILITY, OR TORT (INCLUDING
  * NEGLIGENCE OR OTHERWISE) ARISING IN ANY WAY OUT OF THE USE OF THIS SOFTWARE,
  * EVEN IF ADVISED OF THE POSSIBILITY OF SUCH DAMAGE.
  *
  ******************************************************************************
  */

#include "FreeRTOS.h"
#include "task.h"
#include "cmsis_os.h"

/* USER CODE BEGIN Includes */
#include "application.h"
/* USER CODE END Includes */

osThreadId audioHandle;
osThreadId GUIHandle;

void audioTask(void const * argument);
void guiTask(void const * argument);

void MX_FREERTOS_Init(void); /* (MISRA C 2004 rule 8.1) */

/* Hook prototypes */

/* Init FreeRTOS */

void MX_FREERTOS_Init(void) {

  /* Create the thread(s) */
  /* definition and creation of audio */
  osThreadDef(audio, audioTask, osPriorityRealtime, 0, 32768);
  audioHandle = osThreadCreate(osThread(audio), NULL);

  /* definition and creation of GUI */
  osThreadDef(GUI, guiTask, osPriorityLow, 0, 32768);
  GUIHandle = osThreadCreate(osThread(GUI), NULL);

}

/* audioTask function */
void audioTask(void const * argument)
{

	/* USER CODE BEGIN audioTask */
	appInit();
	appAudio();
	/* Infinite loop */
	for(;;)
	{
		osDelay(1);
	}
	/* USER CODE END audioTask */
}

/* guiTask function */
void guiTask(void const * argument)
{
	/* USER CODE BEGIN guiTask */
	appGui();
	/* Infinite loop */
	for(;;)
	{
		osDelay(1);
	}
	/* USER CODE END guiTask */
}

/************************ (C) COPYRIGHT STMicroelectronics *****END OF FILE****/
